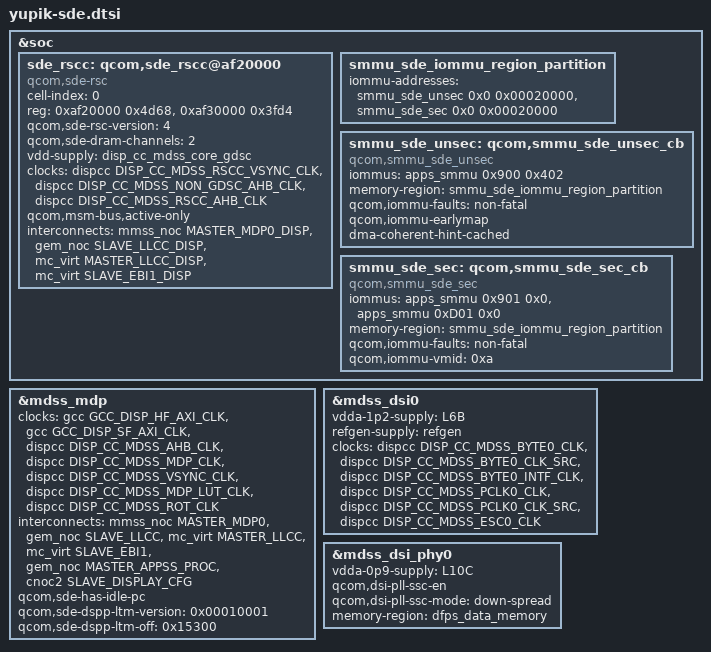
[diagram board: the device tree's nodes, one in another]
#include "yupik-sde-common.dtsi"
#include <dt-bindings/clock/qcom,dispcc-sc7280.h>
#include <dt-bindings/clock/qcom,gcc-sc7280.h>
#include <dt-bindings/clock/qcom,rpmh.h>

&soc {
	sde_rscc: qcom,sde_rscc@af20000 {
		cell-index = <0>;
		compatible = "qcom,sde-rsc";
		reg = <0xaf20000 0x4d68>,
				<0xaf30000 0x3fd4>;
		reg-names = "drv", "wrapper";
		qcom,sde-rsc-version = <4>;

		qcom,sde-dram-channels = <2>;

		vdd-supply = <&disp_cc_mdss_core_gdsc>;
		clocks = <&dispcc DISP_CC_MDSS_RSCC_VSYNC_CLK>,
				<&dispcc DISP_CC_MDSS_NON_GDSC_AHB_CLK>,
				<&dispcc DISP_CC_MDSS_RSCC_AHB_CLK>;
		clock-names = "vsync_clk", "gdsc_clk", "iface_clk";
		qcom,msm-bus,active-only;
		interconnects =
				<&mmss_noc MASTER_MDP0_DISP &gem_noc SLAVE_LLCC_DISP>,
				<&mc_virt MASTER_LLCC_DISP &mc_virt SLAVE_EBI1_DISP>;
		interconnect-names = "qcom,sde-data-bus0",
						"qcom,sde-ebi-bus";
	};

	smmu_sde_iommu_region_partition: smmu_sde_iommu_region_partition {
		iommu-addresses = <&smmu_sde_unsec 0x0 0x00020000>,
				  <&smmu_sde_sec 0x0 0x00020000>;
	};

	smmu_sde_unsec: qcom,smmu_sde_unsec_cb {
		compatible = "qcom,smmu_sde_unsec";
		iommus = <&apps_smmu 0x900 0x402>;
		memory-region = <&smmu_sde_iommu_region_partition>;
		qcom,iommu-faults = "non-fatal";
		qcom,iommu-earlymap; /* for cont-splash */
		dma-coherent-hint-cached;
	};

	smmu_sde_sec: qcom,smmu_sde_sec_cb {
		compatible = "qcom,smmu_sde_sec";
		iommus = <&apps_smmu 0x901 0x0>,
			<&apps_smmu 0xD01 0x0>;
		memory-region = <&smmu_sde_iommu_region_partition>;
		qcom,iommu-faults = "non-fatal";
		qcom,iommu-vmid = <0xa>;
	};
};

&mdss_mdp {
	clocks =
		<&gcc GCC_DISP_HF_AXI_CLK>,
		<&gcc GCC_DISP_SF_AXI_CLK>,
		<&dispcc DISP_CC_MDSS_AHB_CLK>,
		<&dispcc DISP_CC_MDSS_MDP_CLK>,
		<&dispcc DISP_CC_MDSS_VSYNC_CLK>,
		<&dispcc DISP_CC_MDSS_MDP_LUT_CLK>,
		<&dispcc DISP_CC_MDSS_ROT_CLK>;
	clock-names = "gcc_bus", "gcc_nrt_bus",
			"iface_clk", "core_clk", "vsync_clk",
			"lut_clk", "rot_clk";

	/* data and reg bus scale settings */
	interconnects = <&mmss_noc MASTER_MDP0 &gem_noc SLAVE_LLCC>,
			<&mc_virt MASTER_LLCC &mc_virt SLAVE_EBI1>,
			<&gem_noc MASTER_APPSS_PROC
				&cnoc2 SLAVE_DISPLAY_CFG>;
	interconnect-names = "qcom,sde-data-bus0", "qcom,sde-ebi-bus", "qcom,sde-reg-bus";

	qcom,sde-has-idle-pc;
	qcom,sde-dspp-ltm-version = <0x00010001>;
	/* offsets are based off dspp 0 */
	qcom,sde-dspp-ltm-off = <0x15300>;
};

&mdss_dsi0 {
	vdda-1p2-supply = <&L6B>;
	refgen-supply = <&refgen>;
	clocks = <&dispcc DISP_CC_MDSS_BYTE0_CLK>,
		<&dispcc DISP_CC_MDSS_BYTE0_CLK_SRC>,
		<&dispcc DISP_CC_MDSS_BYTE0_INTF_CLK>,
		<&dispcc DISP_CC_MDSS_PCLK0_CLK>,
		<&dispcc DISP_CC_MDSS_PCLK0_CLK_SRC>,
		<&dispcc DISP_CC_MDSS_ESC0_CLK>;
	clock-names = "byte_clk", "byte_clk_rcg", "byte_intf_clk",
			"pixel_clk", "pixel_clk_rcg", "esc_clk";
};

&mdss_dsi_phy0 {
	vdda-0p9-supply = <&L10C>;
	qcom,dsi-pll-ssc-en;
	qcom,dsi-pll-ssc-mode = "down-spread";
	memory-region = <&dfps_data_memory>;

};
